// Description: LIN Description file created using Vector's DaVinci Network Designer

// Created: 07 Sep 2007 14:37:29

// Author: Vector Informatik GmbH

// Version: 0.1

LIN_description_file;
LIN_protocol_version = "ISO17987:2015";
LIN_language_version = "ISO17987:2015";
LDF_file_revision ="14.23.01"; // New optional parameter
LIN_speed = 19.2 kbps;
// LIN_sig_byte_order_big_endian; // New optional parameter

Nodes {
  Master: SeatECU, 5 ms, 0.1 ms ;
  Slaves: Motor1, Motor2 ;
}

Signals {
  Motor1ErrorCode: 8, 5, Motor1, SeatECU ;
  Motor1ErrorValue: 8, 1, Motor1, SeatECU ;
  Motor1LinError: 1, 0, Motor1, SeatECU ;
  Motor1Position: 32, {0, 0, 0, 0}, Motor1, SeatECU ;
  Motor1Selection: 2, 0, SeatECU, Motor1 ;
  Motor1Temp: 8, 5, Motor1, SeatECU ;
  Motor2ErrorCode: 8, 2, Motor2, SeatECU ;
  Motor2ErrorValue: 8, 4, Motor2, SeatECU ;
  Motor2LinError: 1, 0, Motor2, SeatECU ;
  Motor2Position: 32, {0, 0, 0, 0}, Motor2, SeatECU ;
  Motor2Selection: 2, 0, SeatECU, Motor2 ;
  Motor2Temp: 8, 0, Motor2, SeatECU ;
  MotorDirection: 2, 0, SeatECU, Motor1, Motor2 ;
  MotorSpeed: 10, 0, SeatECU, Motor1, Motor2 ;
}

Frames {
  Motor1Control: 48, SeatECU, 1 {
    Motor1Selection, 0 ;
  }
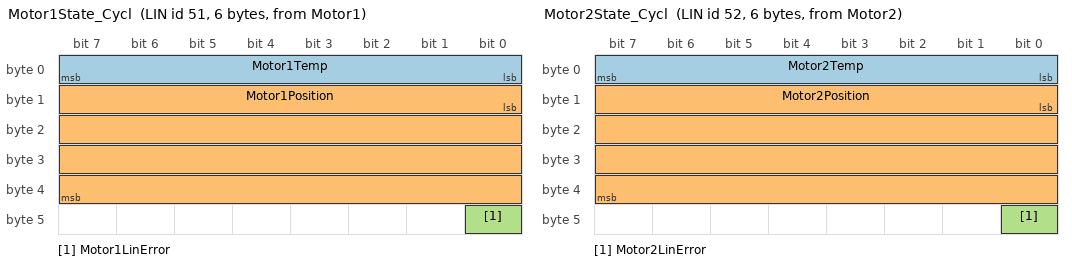
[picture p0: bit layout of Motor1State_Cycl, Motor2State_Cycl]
  Motor1State_Cycl: 51, Motor1, 6 {
    Motor1Temp, 0 ;
    Motor1Position, 8 ;
    Motor1LinError, 40 ;
  }
  Motor1State_Event: 54, Motor1, 3 {
    Motor1ErrorCode, 8 ;
    Motor1ErrorValue, 16 ;
  }
  Motor2Control: 49, SeatECU, 1 {
    Motor2Selection, 0 ;
  }
  Motor2State_Cycl: 52, Motor2, 6 {
    Motor2Temp, 0 ;
    Motor2Position, 8 ;
    Motor2LinError, 40 ;
  }
  Motor2State_Event: 55, Motor2, 3 {
    Motor2ErrorCode, 8 ;
    Motor2ErrorValue, 16 ;
  }
  MotorsControl: 45, SeatECU, 2 {
    MotorDirection, 0 ;
    MotorSpeed, 2 ;
  }
}

Sporadic_frames {
  SporadicControlFrame: Motor1Control, Motor2Control ;
}

Event_triggered_frames {
  ETF_MotorStates: ETFCollisionResolving, 58, Motor1State_Event, Motor2State_Event ;
}

Node_attributes {
  Motor1{
    LIN_protocol = "ISO17987:2015" ;
    configured_NAD = 0x2 ;
    initial_NAD = 0xA ;
    product_id = 0x1E, 0x1, 0 ;
    response_error = Motor1LinError ;
    fault_state_signals = Motor1ErrorValue, Motor1ErrorCode ;
    P2_min = 100 ms ;
    ST_min = 20 ms ;
    N_As_timeout = 1000 ms ;
    N_Cr_timeout = 1000 ms ;
    configurable_frames {
      MotorsControl ;
      Motor1Control ;
      Motor1State_Cycl ;
      Motor1State_Event ;
      ETF_MotorStates ;
    }
  }
  Motor2{
    LIN_protocol = "ISO17987:2015" ;
    configured_NAD = 0x3 ;
    initial_NAD = 0xC ;
    product_id = 0x2E, 0xB, 1 ;
    response_error = Motor2LinError ;
    fault_state_signals = Motor2ErrorValue, Motor2ErrorCode ;
    P2_min = 50 ms ;
    ST_min = 0 ms ;
    N_As_timeout = 1000 ms ;
    N_Cr_timeout = 1000 ms ;
    configurable_frames {
      MotorsControl ;
      Motor2Control ;
      Motor2State_Cycl ;
      Motor2State_Event ;
      ETF_MotorStates ;
    }
  }
}

Schedule_tables {
 NormalTable {
    MotorsControl delay 50 ms ;
    Motor1State_Cycl delay 50 ms ;
    Motor2State_Cycl delay 50 ms ;
    ETF_MotorStates delay 50 ms ;
    SporadicControlFrame delay 20 ms ;
  }
 ETFCollisionResolving {
    Motor1State_Event delay 50 ms ;
    Motor2State_Event delay 50 ms ;
  }
 InitTable {
    AssignNAD { Motor1 } delay 10 ms ;
    SlaveResp delay 10 ms ;
    AssignNAD { Motor2 } delay 10 ms ;
    SlaveResp delay 10 ms ;
    AssignFrameIdRange { Motor1, 0 } delay 10 ms ;
    AssignFrameIdRange { Motor1, 4 } delay 10 ms ;
    AssignFrameIdRange { Motor2, 0 } delay 10 ms ;
    AssignFrameIdRange { Motor2, 4 } delay 10 ms ;
  }
  MasterReqTable {
    MasterReq delay 10 ms ;
  }
  SlaveRespTable {
    SlaveResp delay 10 ms ;
  }
}

Signal_encoding_types {
  encTemperature {
    physical_value, 0, 80, 0.5, -20, "Degree" ;
  }
  MotorSpeed {
    physical_value, 0, 0, 1, 0, "rpm" ;
  }
}

Signal_representation {
  encTemperature: Motor1Temp, Motor2Temp ;
  MotorSpeed: MotorSpeed ;
}
